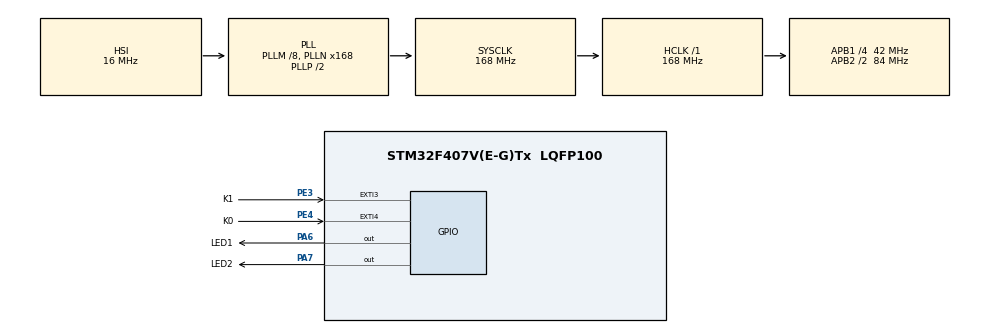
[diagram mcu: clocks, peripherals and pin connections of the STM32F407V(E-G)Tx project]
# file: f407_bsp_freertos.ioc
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FREERTOS.Tasks01=defaultTask,24,128,StartDefaultTask,Default,NULL,Dynamic,NULL,NULL
FREERTOS.configUSE_NEWLIB_REENTRANT=1
Mcu.Family=STM32F4
Mcu.Name=STM32F407V(E-G)Tx
Mcu.Package=LQFP100
NVIC.EXTI3_IRQn=true\:5\:0\:false\:false\:true\:true\:true\:true\:true
NVIC.EXTI4_IRQn=true\:5\:0\:false\:false\:true\:true\:true\:true\:true
NVIC.PriorityGroup=NVIC_PRIORITYGROUP_4
NVIC.TIM6_DAC_IRQn=true\:15\:0\:false\:false\:true\:false\:false\:true\:true
NVIC.TimeBase=TIM6_DAC_IRQn
NVIC.TimeBaseIP=TIM6
PA13.Mode=Trace_Asynchronous_SW
PA13.Signal=SYS_JTMS-SWDIO
PA14.Mode=Trace_Asynchronous_SW
PA14.Signal=SYS_JTCK-SWCLK
PA6.GPIO_Label=LED1
PA6.Signal=GPIO_Output
PA7.GPIO_Label=LED2
PA7.Signal=GPIO_Output
PB3.Mode=Trace_Asynchronous_SW
PB3.Signal=SYS_JTDO-SWO
PC14-OSC32_IN.Mode=LSE-External-Oscillator
PC14-OSC32_IN.Signal=RCC_OSC32_IN
PC15-OSC32_OUT.Mode=LSE-External-Oscillator
PC15-OSC32_OUT.Signal=RCC_OSC32_OUT
PE3.GPIO_Label=K1
PE3.GPIO_ModeDefaultEXTI=GPIO_MODE_IT_FALLING
PE3.GPIO_PuPd=GPIO_PULLUP
PE3.Signal=GPXTI3
PE4.GPIO_Label=K0
PE4.GPIO_ModeDefaultEXTI=GPIO_MODE_IT_FALLING
PE4.GPIO_PuPd=GPIO_PULLUP
PE4.Signal=GPXTI4
PH0-OSC_IN.Mode=HSE-External-Oscillator
PH0-OSC_IN.Signal=RCC_OSC_IN
PH1-OSC_OUT.Mode=HSE-External-Oscillator
PH1-OSC_OUT.Signal=RCC_OSC_OUT
ProjectManager.HeapSize=0x200
ProjectManager.StackSize=0x400
ProjectManager.TargetToolchain=CMake
RCC.48MHZClocksFreq_Value=84000000
RCC.AHBFreq_Value=168000000
RCC.APB1CLKDivider=RCC_HCLK_DIV4
RCC.APB1Freq_Value=42000000
RCC.APB1TimFreq_Value=84000000
RCC.APB2CLKDivider=RCC_HCLK_DIV2
RCC.APB2Freq_Value=84000000
RCC.APB2TimFreq_Value=168000000
RCC.CortexFreq_Value=168000000
RCC.HCLKFreq_Value=168000000
RCC.HSE_VALUE=25000000
RCC.HSI_VALUE=16000000
RCC.PLLM=8
RCC.PLLN=168
RCC.SYSCLKFreq_VALUE=168000000
RCC.SYSCLKSource=RCC_SYSCLKSOURCE_PLLCLK
RCC.VCOOutputFreq_Value=336000000
VP_FREERTOS_VS_CMSIS_V2.Mode=CMSIS_V2
VP_SYS_VS_tim6.Mode=TIM6
board=custom

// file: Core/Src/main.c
/* USER CODE BEGIN Header */
/**
  ******************************************************************************
  * @file           : main.c
  * @brief          : Main program body
  ******************************************************************************
  * @attention
  *
  * Copyright (c) 2026 STMicroelectronics.
  * All rights reserved.
  *
  * This software is licensed under terms that can be found in the LICENSE file
  * in the root directory of this software component.
  * If no LICENSE file comes with this software, it is provided AS-IS.
  *
  ******************************************************************************
  */
/* USER CODE END Header */
#include "main.h"
#include "cmsis_os.h"
#include "gpio.h"

/* USER CODE BEGIN Includes */
#include "bsp.h"
/* USER CODE END Includes */

void SystemClock_Config(void);
void MX_FREERTOS_Init(void);
/* USER CODE BEGIN PFP */
// extern void BSP_Test_Start(void);
/* USER CODE END PFP */

int main(void)
{
  /* Reset of all peripherals, Initializes the Flash interface and the Systick. */
  HAL_Init();

  /* Configure the system clock */
  SystemClock_Config();

  /* Initialize all configured peripherals */
  MX_GPIO_Init();

  /* Init scheduler */
  osKernelInitialize();  /* Call init function for freertos objects (in cmsis_os2.c) */

  MX_FREERTOS_Init();
  BSP_Init();

  /* Start scheduler */
  osKernelStart();

  /* We should never get here as control is now taken by the scheduler */

  /* Infinite loop */
  /* USER CODE BEGIN WHILE */
  while (1)
  {

  }
  /* USER CODE END 3 */
}

void SystemClock_Config(void)
{
  RCC_OscInitTypeDef RCC_OscInitStruct = {0};
  RCC_ClkInitTypeDef RCC_ClkInitStruct = {0};

  /** Configure the main internal regulator output voltage
  */
  __HAL_RCC_PWR_CLK_ENABLE();
  __HAL_PWR_VOLTAGESCALING_CONFIG(PWR_REGULATOR_VOLTAGE_SCALE1);

  /** Initializes the RCC Oscillators according to the specified parameters
  * in the RCC_OscInitTypeDef structure.
  */
  RCC_OscInitStruct.OscillatorType = RCC_OSCILLATORTYPE_HSI;
  RCC_OscInitStruct.HSIState = RCC_HSI_ON;
  RCC_OscInitStruct.HSICalibrationValue = RCC_HSICALIBRATION_DEFAULT;
  RCC_OscInitStruct.PLL.PLLState = RCC_PLL_ON;
  RCC_OscInitStruct.PLL.PLLSource = RCC_PLLSOURCE_HSI;
  RCC_OscInitStruct.PLL.PLLM = 8;
  RCC_OscInitStruct.PLL.PLLN = 168;
  RCC_OscInitStruct.PLL.PLLP = RCC_PLLP_DIV2;
  RCC_OscInitStruct.PLL.PLLQ = 4;
  if (HAL_RCC_OscConfig(&RCC_OscInitStruct) != HAL_OK)
  {
    Error_Handler();
  }

  /** Initializes the CPU, AHB and APB buses clocks
  */
  RCC_ClkInitStruct.ClockType = RCC_CLOCKTYPE_HCLK|RCC_CLOCKTYPE_SYSCLK
                              |RCC_CLOCKTYPE_PCLK1|RCC_CLOCKTYPE_PCLK2;
  RCC_ClkInitStruct.SYSCLKSource = RCC_SYSCLKSOURCE_PLLCLK;
  RCC_ClkInitStruct.AHBCLKDivider = RCC_SYSCLK_DIV1;
  RCC_ClkInitStruct.APB1CLKDivider = RCC_HCLK_DIV4;
  RCC_ClkInitStruct.APB2CLKDivider = RCC_HCLK_DIV2;

  if (HAL_RCC_ClockConfig(&RCC_ClkInitStruct, FLASH_LATENCY_5) != HAL_OK)
  {
    Error_Handler();
  }
}

void HAL_TIM_PeriodElapsedCallback(TIM_HandleTypeDef *htim)
{
  if (htim->Instance == TIM6)
  {
    HAL_IncTick();
  }
}

void Error_Handler(void)
{
  __disable_irq();
  while (1)
  {
  }
}

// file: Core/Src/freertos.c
/* USER CODE BEGIN Header */
/**
  ******************************************************************************
  * File Name          : freertos.c
  * Description        : Code for freertos applications
  ******************************************************************************
  * @attention
  *
  * Copyright (c) 2026 STMicroelectronics.
  * All rights reserved.
  *
  * This software is licensed under terms that can be found in the LICENSE file
  * in the root directory of this software component.
  * If no LICENSE file comes with this software, it is provided AS-IS.
  *
  ******************************************************************************
  */
/* USER CODE END Header */

#include "FreeRTOS.h"
#include "task.h"
#include "main.h"
#include "cmsis_os.h"
#include "bsp.h"

/* Definitions for defaultTask */
osThreadId_t defaultTaskHandle;
const osThreadAttr_t defaultTask_attributes = {
  .name = "defaultTask",
  .stack_size = 128 * 4,
  .priority = (osPriority_t) osPriorityNormal,
};

// --- Button Callback Handlers ---
static void Test_OnK0Button(BSP_Button_TypeDef btn) {
    BSP_LED_Toggle(BSP_LED1);
}

static void Test_OnK1Button(BSP_Button_TypeDef btn) {
    BSP_LED_Toggle(BSP_LED2);
}

// --- Shared Test Setup ---
static void BSP_Test_RegisterHandlers(void) {
    BSP_Button_RegisterCallback(BSP_BUTTON_K0, Test_OnK0Button);
    BSP_Button_RegisterCallback(BSP_BUTTON_K1, Test_OnK1Button);
}

void StartDefaultTask(void *argument);

void MX_FREERTOS_Init(void); /* (MISRA C 2004 rule 8.1) */

void MX_FREERTOS_Init(void) {
  defaultTaskHandle = osThreadNew(StartDefaultTask, NULL, &defaultTask_attributes);
}

void StartDefaultTask(void *argument)
{
  BSP_Test_RegisterHandlers();

  for (uint8_t i = 0; i < BSP_LED_COUNT; i++) {
      BSP_LED_On((BSP_LED_TypeDef)i);
      osDelay(1000);
      BSP_LED_Off((BSP_LED_TypeDef)i);
  }

  /* Infinite loop */
  for(;;)
  {
    osDelay(500);
  }
  /* USER CODE END StartDefaultTask */
}
